# RZV2L register map
Vendor: Renesas; Series: All Chips; File version: x.xx
Registers are 32-bit, access not given, no defined reset value unless marked. A register's access mark holds for its fields unless they carry their own. Offsets are from the block's base; [hi:lo] are bit positions; {n}, {i} and the like mark numbered series.

## SYSC
Base 0x41020200
0x00 SYS_RAM0_ECC
  [0] VECCEN
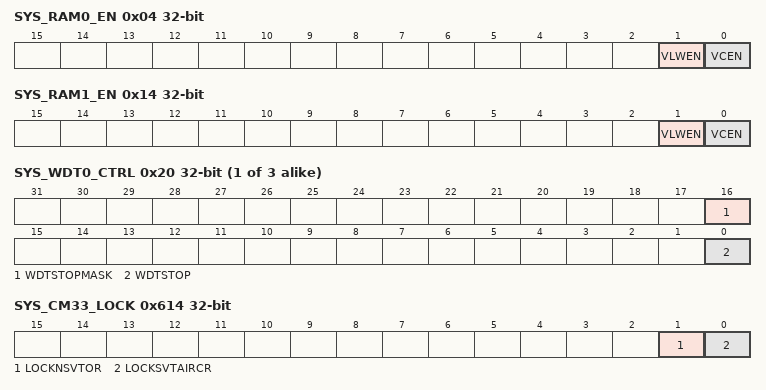
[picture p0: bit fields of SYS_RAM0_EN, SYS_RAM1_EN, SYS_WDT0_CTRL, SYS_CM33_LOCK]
0x04 SYS_RAM0_EN
  [1] VLWEN, [0] VCEN
0x10 SYS_RAM1_ECC
  [0] VECCEN
0x14 SYS_RAM1_EN
  [1] VLWEN, [0] VCEN
{0x20+0x10*i} SYS_WDT{i}_CTRL (i=0..2)
  [16] WDTSTOPMASK, [0] WDTSTOP
0x130 SYS_GETH0_CFG
  [24] FEC_GIGA_ENABLE
0x140 SYS_GETH1_CFG
  [24] FEC_GIGA_ENABLE
{0x200+0x10*i} SYS_I2C{i}_CFG (i=0..3)
  [0] af_bypass
0x604 SYS_CM33_CFG0
  [25:0] CONFIGSSYSTICK
0x608 SYS_CM33_CFG1
  [25:0] CONFIGNSSYSTICK
0x60C SYS_CM33_CFG2
  [31:7] INITSVTOR
0x610 SYS_CM33_CFG3
  [31:7] INITNSVTOR
0x614 SYS_CM33_LOCK
  [1] LOCKNSVTOR, [0] LOCKSVTAIRCR
0x658 SYS_CA55_CFG_RVAL0
  [31:2] RVBARADDRL0
0x65C SYS_CA55_CFG_RVAH0
  [7:0] RVBARADDRH0
0x660 SYS_CA55_CFG_RVAL1
  [31:2] RVBARADDRL1
0x664 SYS_CA55_CFG_RVAH1
  [7:0] RVBARADDRH1
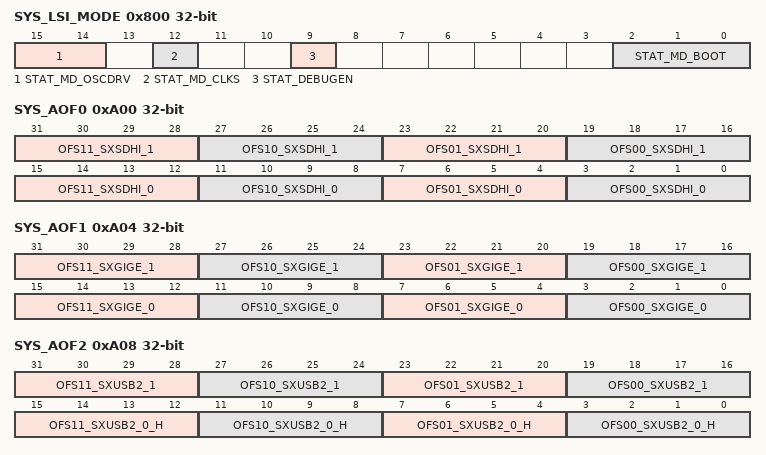
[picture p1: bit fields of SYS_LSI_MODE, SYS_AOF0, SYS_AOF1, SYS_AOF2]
0x800 SYS_LSI_MODE
  [15:14] STAT_MD_OSCDRV, [12] STAT_MD_CLKS, [9] STAT_DEBUGEN, [2:0] STAT_MD_BOOT
0xA00 SYS_AOF0
  [31:28] OFS11_SXSDHI_1, [27:24] OFS10_SXSDHI_1, [23:20] OFS01_SXSDHI_1, [19:16] OFS00_SXSDHI_1, [15:12] OFS11_SXSDHI_0, [11:8] OFS10_SXSDHI_0, [7:4] OFS01_SXSDHI_0, [3:0] OFS00_SXSDHI_0
0xA04 SYS_AOF1
  [31:28] OFS11_SXGIGE_1, [27:24] OFS10_SXGIGE_1, [23:20] OFS01_SXGIGE_1, [19:16] OFS00_SXGIGE_1, [15:12] OFS11_SXGIGE_0, [11:8] OFS10_SXGIGE_0, [7:4] OFS01_SXGIGE_0, [3:0] OFS00_SXGIGE_0
0xA08 SYS_AOF2
  [31:28] OFS11_SXUSB2_1, [27:24] OFS10_SXUSB2_1, [23:20] OFS01_SXUSB2_1, [19:16] OFS00_SXUSB2_1, [15:12] OFS11_SXUSB2_0_H, [11:8] OFS10_SXUSB2_0_H, [7:4] OFS01_SXUSB2_0_H, [3:0] OFS00_SXUSB2_0_H
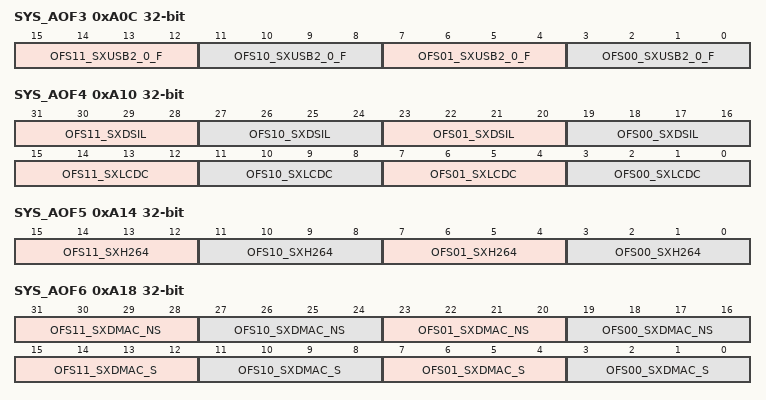
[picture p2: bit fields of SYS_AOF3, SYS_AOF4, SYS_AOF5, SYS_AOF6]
0xA0C SYS_AOF3
  [15:12] OFS11_SXUSB2_0_F, [11:8] OFS10_SXUSB2_0_F, [7:4] OFS01_SXUSB2_0_F, [3:0] OFS00_SXUSB2_0_F
0xA10 SYS_AOF4
  [31:28] OFS11_SXDSIL, [27:24] OFS10_SXDSIL, [23:20] OFS01_SXDSIL, [19:16] OFS00_SXDSIL, [15:12] OFS11_SXLCDC, [11:8] OFS10_SXLCDC, [7:4] OFS01_SXLCDC, [3:0] OFS00_SXLCDC
0xA14 SYS_AOF5
  [15:12] OFS11_SXH264, [11:8] OFS10_SXH264, [7:4] OFS01_SXH264, [3:0] OFS00_SXH264
0xA18 SYS_AOF6
  [31:28] OFS11_SXDMAC_NS, [27:24] OFS10_SXDMAC_NS, [23:20] OFS01_SXDMAC_NS, [19:16] OFS00_SXDMAC_NS, [15:12] OFS11_SXDMAC_S, [11:8] OFS10_SXDMAC_S, [7:4] OFS01_SXDMAC_S, [3:0] OFS00_SXDMAC_S
0xB00 SYS_LP_CTL0
  [0] MAIN_CPU
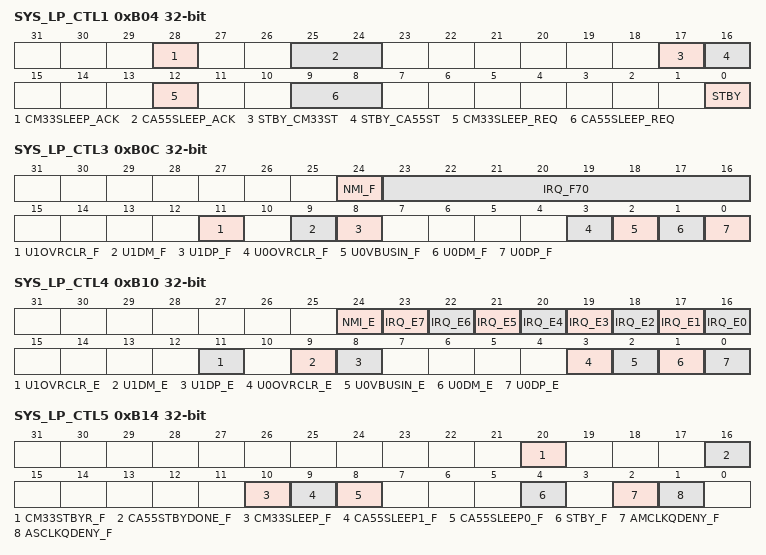
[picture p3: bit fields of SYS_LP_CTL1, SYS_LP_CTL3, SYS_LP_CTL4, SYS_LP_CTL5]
0xB04 SYS_LP_CTL1
  [28] CM33SLEEP_ACK, [25:24] CA55SLEEP_ACK, [17] STBY_CM33ST, [16] STBY_CA55ST, [12] CM33SLEEP_REQ, [9:8] CA55SLEEP_REQ, [0] STBY
0xB08 SYS_LP_CTL2
  [0] CA55_STBYCTL
0xB0C SYS_LP_CTL3
  [24] NMI_F, [23:16] IRQ_F70, [11] U1OVRCLR_F, [9] U1DM_F, [8] U1DP_F, [3] U0OVRCLR_F, [2] U0VBUSIN_F, [1] U0DM_F, [0] U0DP_F
0xB10 SYS_LP_CTL4
  [24] NMI_E, [n+16] IRQ_E{n} (n=0..7), [11] U1OVRCLR_E, [9] U1DM_E, [8] U1DP_E, [3] U0OVRCLR_E, [2] U0VBUSIN_E, [1] U0DM_E, [0] U0DP_E
0xB14 SYS_LP_CTL5
  [20] CM33STBYR_F, [16] CA55STBYDONE_F, [10] CM33SLEEP_F, [9] CA55SLEEP1_F, [8] CA55SLEEP0_F, [4] STBY_F, [2] AMCLKQDENY_F, [1] ASCLKQDENY_F
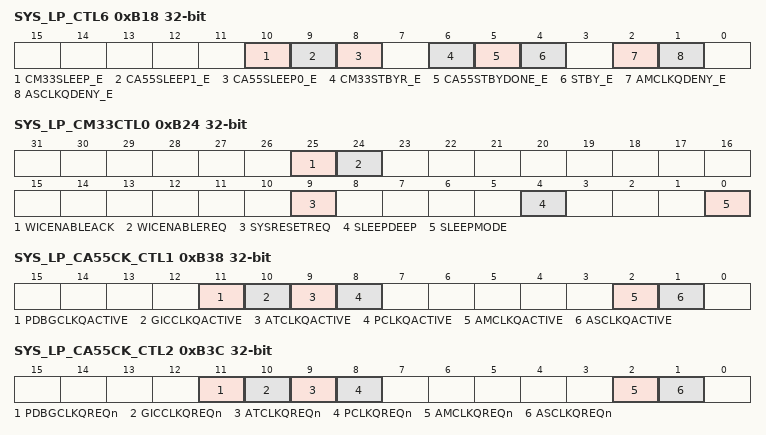
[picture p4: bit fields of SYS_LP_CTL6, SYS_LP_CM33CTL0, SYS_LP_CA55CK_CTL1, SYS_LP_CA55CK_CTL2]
0xB18 SYS_LP_CTL6
  [10] CM33SLEEP_E, [9] CA55SLEEP1_E, [8] CA55SLEEP0_E, [6] CM33STBYR_E, [5] CA55STBYDONE_E, [4] STBY_E, [2] AMCLKQDENY_E, [1] ASCLKQDENY_E
0xB1C SYS_LP_CTL7
  [0] IM33_MASK
0xB20 SYS_LP_CTL8
  [0] SUBCPU_RTRIG
0xB24 SYS_LP_CM33CTL0
  [25] WICENABLEACK, [24] WICENABLEREQ, [9] SYSRESETREQ, [4] SLEEPDEEP, [0] SLEEPMODE
0xB38 SYS_LP_CA55CK_CTL1
  [11] PDBGCLKQACTIVE, [10] GICCLKQACTIVE, [9] ATCLKQACTIVE, [8] PCLKQACTIVE, [2] AMCLKQACTIVE, [1] ASCLKQACTIVE
0xB3C SYS_LP_CA55CK_CTL2
  [11] PDBGCLKQREQn, [10] GICCLKQREQn, [9] ATCLKQREQn, [8] PCLKQREQn, [2] AMCLKQREQn, [1] ASCLKQREQn
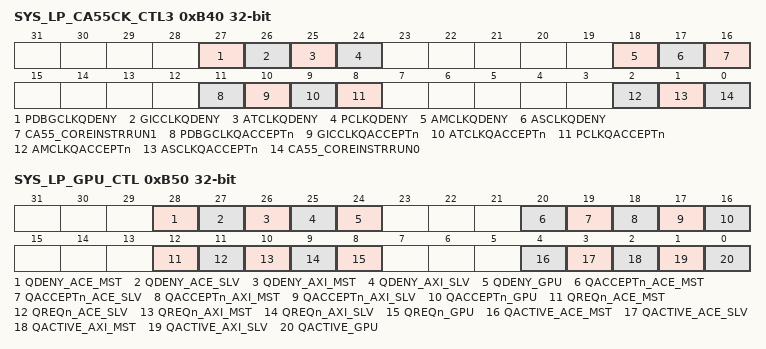
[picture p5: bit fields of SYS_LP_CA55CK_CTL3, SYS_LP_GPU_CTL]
0xB40 SYS_LP_CA55CK_CTL3
  [27] PDBGCLKQDENY, [26] GICCLKQDENY, [25] ATCLKQDENY, [24] PCLKQDENY, [18] AMCLKQDENY, [17] ASCLKQDENY, [16] CA55_COREINSTRRUN1, [11] PDBGCLKQACCEPTn, [10] GICCLKQACCEPTn, [9] ATCLKQACCEPTn, [8] PCLKQACCEPTn, [2] AMCLKQACCEPTn, [1] ASCLKQACCEPTn, [0] CA55_COREINSTRRUN0
0xB50 SYS_LP_GPU_CTL
  [28] QDENY_ACE_MST, [27] QDENY_ACE_SLV, [26] QDENY_AXI_MST, [25] QDENY_AXI_SLV, [24] QDENY_GPU, [20] QACCEPTn_ACE_MST, [19] QACCEPTn_ACE_SLV, [18] QACCEPTn_AXI_MST, [17] QACCEPTn_AXI_SLV, [16] QACCEPTn_GPU, [12] QREQn_ACE_MST, [11] QREQn_ACE_SLV, [10] QREQn_AXI_MST, [9] QREQn_AXI_SLV, [8] QREQn_GPU, [4] QACTIVE_ACE_MST, [3] QACTIVE_ACE_SLV, [2] QACTIVE_AXI_MST, [1] QACTIVE_AXI_SLV, [0] QACTIVE_GPU
{0xC00+4i} SYS_GPREG_{i} (i=0..3)
  [31:0] GPREG{i}
